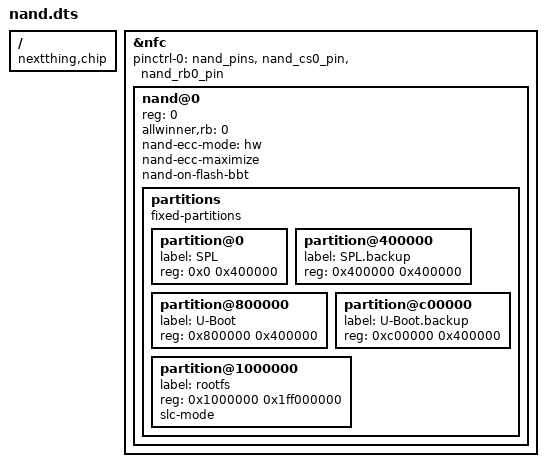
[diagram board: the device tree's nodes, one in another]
/dts-v1/;
/plugin/;

/ {
	compatible = "nextthing,chip", "allwinner,sun5i-r8";

	fragment@0 {
		target = <&nfc>;

		__overlay__ {
			#address-cells = <1>;
			#size-cells = <0>;
			pinctrl-names = "default";
			pinctrl-0 = <&nand_pins &nand_cs0_pin &nand_rb0_pin>;
			status = "okay";

			nand@0 {
				reg = <0>;
				allwinner,rb = <0>;
				nand-ecc-mode = "hw";
				nand-ecc-maximize;
				nand-on-flash-bbt;

				partitions {
					compatible = "fixed-partitions";
					#address-cells = <2>;
					#size-cells = <2>;

					partition@0 {
						label = "SPL";
						reg = /bits/ 64 <0x0 0x400000>;
					};

					partition@400000 {
						label = "SPL.backup";
						reg = /bits/ 64 <0x400000 0x400000>;
					};

					partition@800000 {
						label = "U-Boot";
						reg = /bits/ 64 <0x800000 0x400000>;
					};

					partition@c00000 {
						label = "U-Boot.backup";
						reg = /bits/ 64 <0xc00000 0x400000>;
					};

					partition@1000000 {
						label = "rootfs";
						reg = /bits/ 64 <0x1000000 0x1ff000000>;
						slc-mode;
					};
				};
			};
		};
	};
};
